# STM32F410xx register map
File version: 1.0
Registers are 32-bit, read-write, reset 0x0 unless marked. A register's access mark holds for its fields unless they carry their own. Offsets are from the block's base; [hi:lo] are bit positions; {n}, {i} and the like mark numbered series.

## NVIC — Nested Vectored Interrupt Controller
Base 0xE000E000
0x04 ICTR ro — Interrupt Controller Type Register
  [3:0] INTLINESNUM — Total number of interrupt lines in groups
{0x100+4i} ISER{i} (i=0..2) — Interrupt Set-Enable Register
  [31:0] SETENA
{0x180+4i} ICER{i} (i=0..2) — Interrupt Clear-Enable Register
  [31:0] CLRENA
{0x200+4i} ISPR{i} (i=0..2) — Interrupt Set-Pending Register
  [31:0] SETPEND
{0x280+4i} ICPR{i} (i=0..2) — Interrupt Clear-Pending Register
  [31:0] CLRPEND
{0x300+4i} IABR{i} ro (i=0..2) — Interrupt Active Bit Register
  [31:0] ACTIVE
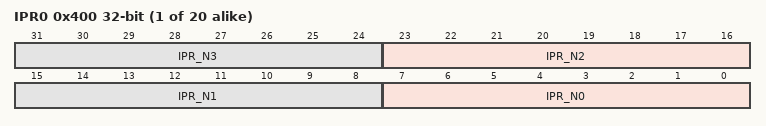
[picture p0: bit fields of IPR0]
{0x400+4i} IPR{i} (i=0..19) — Interrupt Priority Register
  [8n+7:8n] IPR_N{n} (n=0..3)
0xF00 STIR wo — Software Triggered Interrupt Register
  [8:0] INTID — interrupt to be triggered

## TIM6 — Basic timers
Base 0x40001000
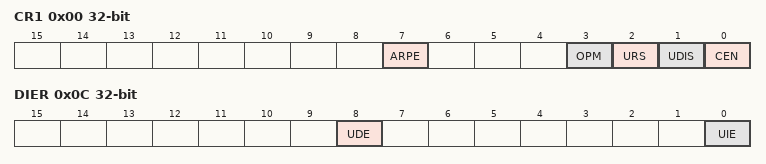
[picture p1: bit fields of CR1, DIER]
0x00 CR1 — control register 1
  [7] ARPE — Auto-reload preload enable
  [3] OPM — One-pulse mode
  [2] URS — Update request source
  [1] UDIS — Update disable
  [0] CEN — Counter enable
0x04 CR2 — control register 2
  [6:4] MMS — Master mode selection
0x0C DIER — DMA/Interrupt enable register
  [8] UDE — Update DMA request enable
  [0] UIE — Update interrupt enable
0x10 SR — status register
  [0] UIF — Update interrupt flag
0x14 EGR wo — event generation register
  [0] UG — Update generation
0x24 CNT — counter
  [15:0] CNT — Low counter value
0x28 PSC — prescaler
  [15:0] PSC — Prescaler value
0x2C ARR — auto-reload register
  [15:0] ARR — Low Auto-reload value

## RNG — Random number generator
Base 0x40080000
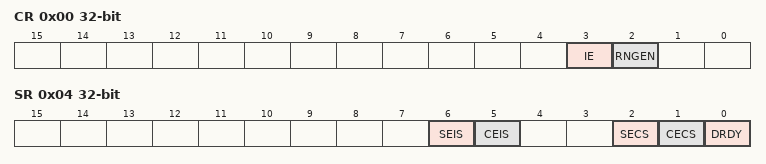
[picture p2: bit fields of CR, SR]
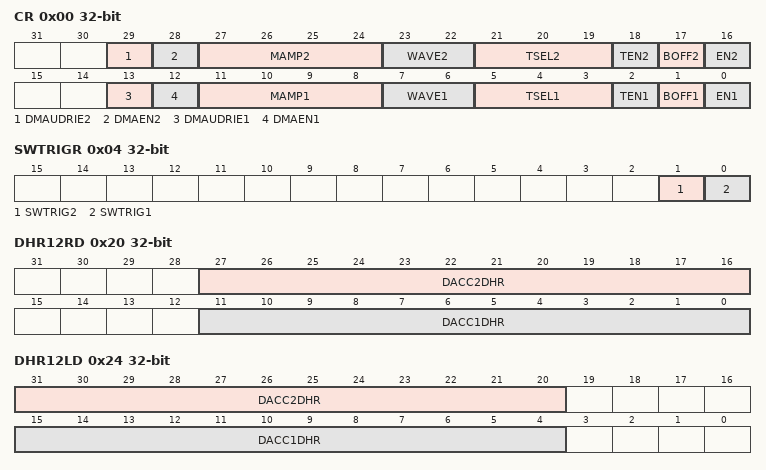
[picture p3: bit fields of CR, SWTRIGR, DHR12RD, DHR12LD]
0x00 CR — control register
  [3] IE — Interrupt enable
  [2] RNGEN — Random number generator enable
0x04 SR access per field — status register
  [6] SEIS rw — Seed error interrupt status
  [5] CEIS rw — Clock error interrupt status
  [2] SECS ro — Seed error current status
  [1] CECS ro — Clock error current status
  [0] DRDY ro — Data ready
0x08 DR ro — data register
  [31:0] RNDATA — Random data

## DAC — Digital-to-analog converter
Base 0x40007400
0x00 CR — control register
  [29] DMAUDRIE2 — DAC channel2 DMA underrun interrupt enable
  [28] DMAEN2 — DAC channel2 DMA enable
  [27:24] MAMP2 — DAC channel2 mask/amplitude selector
  [23:22] WAVE2 — DAC channel2 noise/triangle wave generation enable
  [21:19] TSEL2 — DAC channel2 trigger selection
  [18] TEN2 — DAC channel2 trigger enable
  [17] BOFF2 — DAC channel2 output buffer disable
  [16] EN2 — DAC channel2 enable
  [13] DMAUDRIE1 — DAC channel1 DMA Underrun Interrupt enable
  [12] DMAEN1 — DAC channel1 DMA enable
  [11:8] MAMP1 — DAC channel1 mask/amplitude selector
  [7:6] WAVE1 — DAC channel1 noise/triangle wave generation enable
  [5:3] TSEL1 — DAC channel1 trigger selection
  [2] TEN1 — DAC channel1 trigger enable
  [1] BOFF1 — DAC channel1 output buffer disable
  [0] EN1 — DAC channel1 enable
0x04 SWTRIGR wo — software trigger register
  [1] SWTRIG2 — DAC channel2 software trigger
  [0] SWTRIG1 — DAC channel1 software trigger
0x08 DHR12R1 — channel1 12-bit right-aligned data holding register
  [11:0] DACC1DHR — DAC channel1 12-bit right-aligned data
0x0C DHR12L1 — channel1 12-bit left aligned data holding register
  [15:4] DACC1DHR — DAC channel1 12-bit left-aligned data
0x10 DHR8R1 — channel1 8-bit right aligned data holding register
  [7:0] DACC1DHR — DAC channel1 8-bit right-aligned data
0x14 DHR12R2 — channel2 12-bit right aligned data holding register
  [11:0] DACC2DHR — DAC channel2 12-bit right-aligned data
0x18 DHR12L2 — channel2 12-bit left aligned data holding register
  [15:4] DACC2DHR — DAC channel2 12-bit left-aligned data
0x1C DHR8R2 — channel2 8-bit right-aligned data holding register
  [7:0] DACC2DHR — DAC channel2 8-bit right-aligned data
0x20 DHR12RD — Dual DAC 12-bit right-aligned data holding register
  [27:16] DACC2DHR — DAC channel2 12-bit right-aligned data
  [11:0] DACC1DHR — DAC channel1 12-bit right-aligned data
0x24 DHR12LD — DUAL DAC 12-bit left aligned data holding register
  [31:20] DACC2DHR — DAC channel2 12-bit left-aligned data
  [15:4] DACC1DHR — DAC channel1 12-bit left-aligned data
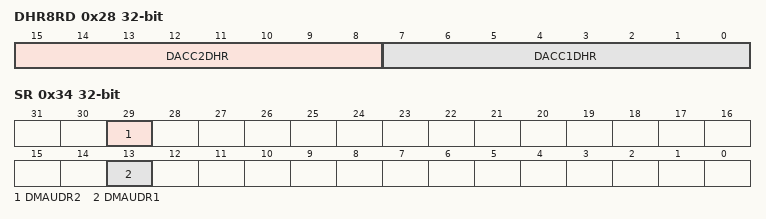
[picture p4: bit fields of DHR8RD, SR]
0x28 DHR8RD — DUAL DAC 8-bit right aligned data holding register
  [15:8] DACC2DHR — DAC channel2 8-bit right-aligned data
  [7:0] DACC1DHR — DAC channel1 8-bit right-aligned data
0x2C DOR1 ro — channel1 data output register
  [11:0] DACC1DOR — DAC channel1 data output
0x30 DOR2 ro — channel2 data output register
  [11:0] DACC2DOR — DAC channel2 data output
0x34 SR — status register
  [29] DMAUDR2 — DAC channel2 DMA underrun flag
  [13] DMAUDR1 — DAC channel1 DMA underrun flag
